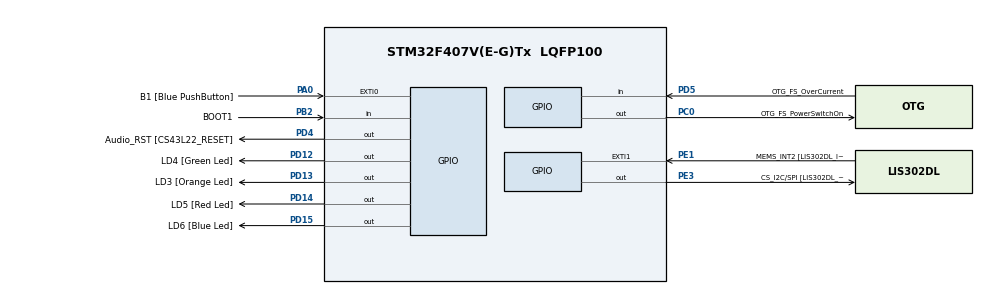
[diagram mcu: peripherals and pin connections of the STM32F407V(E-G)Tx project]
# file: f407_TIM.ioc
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Mcu.Family=STM32F4
Mcu.Name=STM32F407V(E-G)Tx
Mcu.Package=LQFP100
NVIC.PriorityGroup=NVIC_PRIORITYGROUP_0
NVIC.TIM1_UP_TIM10_IRQn=true\:0\:0\:false\:false\:true\:true\:true
PA0-WKUP.GPIO_Label=B1 [Blue PushButton]
PA0-WKUP.Signal=GPXTI0
PA10.GPIO_Label=OTG_FS_ID
PA10.GPIO_Mode=GPIO_MODE_AF_PP
PA10.GPIO_PuPd=GPIO_NOPULL
PA10.GPIO_Speed=GPIO_SPEED_FREQ_LOW
PA10.Signal=USB_OTG_FS_ID
PA11.GPIO_Label=OTG_FS_DM
PA11.GPIO_Mode=GPIO_MODE_AF_PP
PA11.GPIO_PuPd=GPIO_NOPULL
PA11.GPIO_Speed=GPIO_SPEED_FREQ_LOW
PA11.Signal=USB_OTG_FS_DM
PA12.GPIO_Label=OTG_FS_DP
PA12.GPIO_Mode=GPIO_MODE_AF_PP
PA12.GPIO_PuPd=GPIO_NOPULL
PA12.GPIO_Speed=GPIO_SPEED_FREQ_LOW
PA12.Signal=USB_OTG_FS_DP
PA13.GPIO_Label=SWDIO
PA13.Signal=SYS_JTMS-SWDIO
PA14.GPIO_Label=SWCLK
PA14.Signal=SYS_JTCK-SWCLK
PA4.GPIO_Label=I2S3_WS [CS43L22_LRCK]
PA4.GPIO_Mode=GPIO_MODE_AF_PP
PA4.GPIO_PuPd=GPIO_NOPULL
PA4.GPIO_Speed=GPIO_SPEED_FREQ_LOW
PA4.Signal=I2S3_WS
PA5.GPIO_Label=SPI1_SCK [LIS302DL_SCL/SPC]
PA5.GPIO_Mode=GPIO_MODE_AF_PP
PA5.GPIO_PuPd=GPIO_NOPULL
PA5.GPIO_Speed=GPIO_SPEED_FREQ_LOW
PA5.Signal=SPI1_SCK
PA6.GPIO_Label=SPI1_MISO [LIS302DL_SDO]
PA6.GPIO_Mode=GPIO_MODE_AF_PP
PA6.GPIO_PuPd=GPIO_NOPULL
PA6.GPIO_Speed=GPIO_SPEED_FREQ_LOW
PA6.Signal=SPI1_MISO
PA7.GPIO_Label=SPI1_MOSI [LIS302DL_SDA/SDI/SDO]
PA7.GPIO_Mode=GPIO_MODE_AF_PP
PA7.GPIO_PuPd=GPIO_NOPULL
PA7.GPIO_Speed=GPIO_SPEED_FREQ_LOW
PA7.Signal=SPI1_MOSI
PA9.GPIO_Label=VBUS_FS
PA9.GPIO_Mode=GPIO_MODE_INPUT
PA9.GPIO_PuPd=GPIO_NOPULL
PA9.Signal=USB_OTG_FS_VBUS
PB10.GPIO_Label=CLK_IN [MP45DT02_CLK]
PB10.GPIO_Mode=GPIO_MODE_AF_PP
PB10.GPIO_PuPd=GPIO_NOPULL
PB10.GPIO_Speed=GPIO_SPEED_FREQ_LOW
PB10.Signal=I2S2_CK
PB2.GPIO_Label=BOOT1
PB2.GPIO_Mode=GPIO_MODE_INPUT
PB2.GPIO_PuPd=GPIO_NOPULL
PB2.Signal=GPIO_Input
PB3.GPIO_Label=SWO
PB3.Signal=SYS_JTDO-SWO
PB6.GPIO_Label=Audio_SCL [CS43L22_SCL]
PB6.GPIO_Mode=GPIO_MODE_AF_OD
PB6.GPIO_PuPd=GPIO_NOPULL
PB6.GPIO_Speed=GPIO_SPEED_FREQ_LOW
PB6.Signal=I2C1_SCL
PB9.GPIO_Label=Audio_SDA [CS43L22_SDA]
PB9.GPIO_Mode=GPIO_MODE_AF_OD
PB9.GPIO_PuPd=GPIO_NOPULL
PB9.GPIO_Speed=GPIO_SPEED_FREQ_LOW
PB9.Signal=I2C1_SDA
PC0.GPIO_Label=OTG_FS_PowerSwitchOn
PC0.GPIO_PuPd=GPIO_NOPULL
PC0.GPIO_Speed=GPIO_SPEED_FREQ_LOW
PC0.PinState=GPIO_PIN_SET
PC0.Signal=GPIO_Output
PC10.GPIO_Label=I2S3_SCK [CS43L22_SCLK]
PC10.GPIO_Mode=GPIO_MODE_AF_PP
PC10.GPIO_PuPd=GPIO_NOPULL
PC10.GPIO_Speed=GPIO_SPEED_FREQ_LOW
PC10.Signal=I2S3_CK
PC12.GPIO_Label=I2S3_SD [CS43L22_SDIN]
PC12.GPIO_Mode=GPIO_MODE_AF_PP
PC12.GPIO_PuPd=GPIO_NOPULL
PC12.GPIO_Speed=GPIO_SPEED_FREQ_LOW
PC12.Signal=I2S3_SD
PC14-OSC32_IN.GPIO_Label=PC14-OSC32_IN
PC14-OSC32_IN.Signal=RCC_OSC32_IN
PC15-OSC32_OUT.GPIO_Label=PC15-OSC32_OUT
PC15-OSC32_OUT.Signal=RCC_OSC32_OUT
PC3.GPIO_Label=PDM_OUT [MP45DT02_DOUT]
PC3.GPIO_Mode=GPIO_MODE_AF_PP
PC3.GPIO_PuPd=GPIO_NOPULL
PC3.GPIO_Speed=GPIO_SPEED_FREQ_LOW
PC3.Signal=I2S2_SD
PC7.GPIO_Label=I2S3_MCK [CS43L22_MCLK]
PC7.GPIO_Mode=GPIO_MODE_AF_PP
PC7.GPIO_PuPd=GPIO_NOPULL
PC7.GPIO_Speed=GPIO_SPEED_FREQ_LOW
PC7.Signal=I2S3_MCK
PD12.GPIO_Label=LD4 [Green Led]
PD12.GPIO_PuPd=GPIO_NOPULL
PD12.GPIO_Speed=GPIO_SPEED_FREQ_LOW
PD12.Signal=GPIO_Output
PD13.GPIO_Label=LD3 [Orange Led]
PD13.GPIO_PuPd=GPIO_NOPULL
PD13.GPIO_Speed=GPIO_SPEED_FREQ_LOW
PD13.Signal=GPIO_Output
PD14.GPIO_Label=LD5 [Red Led]
PD14.GPIO_PuPd=GPIO_NOPULL
PD14.GPIO_Speed=GPIO_SPEED_FREQ_LOW
PD14.Signal=GPIO_Output
PD15.GPIO_Label=LD6 [Blue Led]
PD15.GPIO_PuPd=GPIO_NOPULL
PD15.GPIO_Speed=GPIO_SPEED_FREQ_LOW
PD15.Signal=GPIO_Output
PD4.GPIO_Label=Audio_RST [CS43L22_RESET]
PD4.GPIO_PuPd=GPIO_NOPULL
PD4.GPIO_Speed=GPIO_SPEED_FREQ_LOW
PD4.Signal=GPIO_Output
PD5.GPIO_Label=OTG_FS_OverCurrent
PD5.GPIO_Mode=GPIO_MODE_INPUT
PD5.GPIO_PuPd=GPIO_NOPULL
PD5.Signal=GPIO_Input
PE1.GPIO_Label=MEMS_INT2 [LIS302DL_INT2]
PE1.GPIO_ModeDefaultEXTI=GPIO_MODE_EVT_RISING
PE1.GPIO_PuPd=GPIO_NOPULL
PE1.Signal=GPXTI1
PE3.GPIO_Label=CS_I2C/SPI [LIS302DL_CS_I2C/SPI]
PE3.GPIO_PuPd=GPIO_NOPULL
PE3.GPIO_Speed=GPIO_SPEED_FREQ_LOW
PE3.Signal=GPIO_Output
PH0-OSC_IN.GPIO_Label=PH0-OSC_IN
PH0-OSC_IN.Mode=HSE-External-Oscillator
PH0-OSC_IN.Signal=RCC_OSC_IN
PH1-OSC_OUT.GPIO_Label=PH1-OSC_OUT
PH1-OSC_OUT.Mode=HSE-External-Oscillator
PH1-OSC_OUT.Signal=RCC_OSC_OUT
ProjectManager.HeapSize=0x200
ProjectManager.StackSize=0x400
ProjectManager.TargetToolchain=STM32CubeIDE
RCC.48MHZClocksFreq_Value=48000000
RCC.AHBFreq_Value=168000000
RCC.APB1CLKDivider=RCC_HCLK_DIV4
RCC.APB1Freq_Value=42000000
RCC.APB1TimFreq_Value=84000000
RCC.APB2CLKDivider=RCC_HCLK_DIV2
RCC.APB2Freq_Value=84000000
RCC.APB2TimFreq_Value=168000000
RCC.CortexFreq_Value=168000000
RCC.HCLKFreq_Value=168000000
RCC.HSE_VALUE=8000000
RCC.HSI_VALUE=16000000
RCC.LSE_VALUE=32768
RCC.PLLM=4
RCC.PLLN=168
RCC.PLLQ=7
RCC.PLLSourceVirtual=RCC_PLLSOURCE_HSE
RCC.SYSCLKFreq_VALUE=168000000
RCC.SYSCLKSource=RCC_SYSCLKSOURCE_PLLCLK
RCC.VCOOutputFreq_Value=336000000
TIM1.ClockDivision=TIM_CLOCKDIVISION_DIV1
TIM1.Period=9999
TIM1.Prescaler=8399
VP_TIM1_VS_ClockSourceINT.Mode=Internal
board=STM32F407G-DISC1

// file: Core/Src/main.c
/* USER CODE BEGIN Header */
/**
  ******************************************************************************
  * @file           : main.c
  * @brief          : Main program body
  ******************************************************************************
  * @attention
  *
  * <h2><center>&copy; Copyright (c) 2020 STMicroelectronics.
  * All rights reserved.</center></h2>
  *
  * This software component is licensed by ST under BSD 3-Clause license,
  * the "License"; You may not use this file except in compliance with the
  * License. You may obtain a copy of the License at:
  *                        opensource.org/licenses/BSD-3-Clause
  *
  ******************************************************************************
  */
/* USER CODE END Header */
#include "main.h"

void SystemClock_Config(void);
static void MX_GPIO_Init(void);
static void MX_TIM1_Init(void);

int main(void)
{

  /* MCU Configuration--------------------------------------------------------*/

  /* Reset of all peripherals, Initializes the Flash interface and the Systick. */

  LL_APB2_GRP1_EnableClock(LL_APB2_GRP1_PERIPH_SYSCFG);
  LL_APB1_GRP1_EnableClock(LL_APB1_GRP1_PERIPH_PWR);

  NVIC_SetPriorityGrouping(NVIC_PRIORITYGROUP_0);

  /* System interrupt init*/

  /* Configure the system clock */
  SystemClock_Config();

  /* Initialize all configured peripherals */
  MX_GPIO_Init();
  MX_TIM1_Init();

  /* Infinite loop */
  while (1)
  {

  }
}

void SystemClock_Config(void)
{
  LL_FLASH_SetLatency(LL_FLASH_LATENCY_5);
  while(LL_FLASH_GetLatency()!= LL_FLASH_LATENCY_5)
  {
  }
  LL_PWR_SetRegulVoltageScaling(LL_PWR_REGU_VOLTAGE_SCALE1);
  LL_RCC_HSE_Enable();

   /* Wait till HSE is ready */
  while(LL_RCC_HSE_IsReady() != 1)
  {

  }
  LL_RCC_PLL_ConfigDomain_SYS(LL_RCC_PLLSOURCE_HSE, LL_RCC_PLLM_DIV_4, 168, LL_RCC_PLLP_DIV_2);
  LL_RCC_PLL_Enable();

   /* Wait till PLL is ready */
  while(LL_RCC_PLL_IsReady() != 1)
  {

  }
  LL_RCC_SetAHBPrescaler(LL_RCC_SYSCLK_DIV_1);
  LL_RCC_SetAPB1Prescaler(LL_RCC_APB1_DIV_4);
  LL_RCC_SetAPB2Prescaler(LL_RCC_APB2_DIV_2);
  LL_RCC_SetSysClkSource(LL_RCC_SYS_CLKSOURCE_PLL);

   /* Wait till System clock is ready */
  while(LL_RCC_GetSysClkSource() != LL_RCC_SYS_CLKSOURCE_STATUS_PLL)
  {

  }
  LL_Init1msTick(168000000);
  LL_SetSystemCoreClock(168000000);
}

static void MX_TIM1_Init(void)
{

  LL_TIM_InitTypeDef TIM_InitStruct = {0};

  /* Peripheral clock enable */
  LL_APB2_GRP1_EnableClock(LL_APB2_GRP1_PERIPH_TIM1);

  /* TIM1 interrupt Init */
  NVIC_SetPriority(TIM1_UP_TIM10_IRQn, NVIC_EncodePriority(NVIC_GetPriorityGrouping(),0, 0));
  NVIC_EnableIRQ(TIM1_UP_TIM10_IRQn);

  TIM_InitStruct.Prescaler = 8399;
  TIM_InitStruct.CounterMode = LL_TIM_COUNTERMODE_UP;
  TIM_InitStruct.Autoreload = 9999;
  TIM_InitStruct.ClockDivision = LL_TIM_CLOCKDIVISION_DIV1;
  TIM_InitStruct.RepetitionCounter = 0;
  LL_TIM_Init(TIM1, &TIM_InitStruct);
  LL_TIM_DisableARRPreload(TIM1);
  LL_TIM_SetClockSource(TIM1, LL_TIM_CLOCKSOURCE_INTERNAL);
  LL_TIM_SetTriggerOutput(TIM1, LL_TIM_TRGO_RESET);
  LL_TIM_DisableMasterSlaveMode(TIM1);
  /* USER CODE BEGIN TIM1_Init 2 */
  LL_TIM_EnableCounter(TIM1);
  LL_TIM_EnableIT_UPDATE(TIM1);
  /* USER CODE END TIM1_Init 2 */

}

static void MX_GPIO_Init(void)
{
  LL_EXTI_InitTypeDef EXTI_InitStruct = {0};
  LL_GPIO_InitTypeDef GPIO_InitStruct = {0};

  /* GPIO Ports Clock Enable */
  LL_AHB1_GRP1_EnableClock(LL_AHB1_GRP1_PERIPH_GPIOE);
  LL_AHB1_GRP1_EnableClock(LL_AHB1_GRP1_PERIPH_GPIOC);
  LL_AHB1_GRP1_EnableClock(LL_AHB1_GRP1_PERIPH_GPIOH);
  LL_AHB1_GRP1_EnableClock(LL_AHB1_GRP1_PERIPH_GPIOA);
  LL_AHB1_GRP1_EnableClock(LL_AHB1_GRP1_PERIPH_GPIOB);
  LL_AHB1_GRP1_EnableClock(LL_AHB1_GRP1_PERIPH_GPIOD);

  /**/
  LL_GPIO_ResetOutputPin(CS_I2C_SPI_GPIO_Port, CS_I2C_SPI_Pin);

  /**/
  LL_GPIO_ResetOutputPin(GPIOD, LD4_Pin|LD3_Pin|LD5_Pin|LD6_Pin
                          |Audio_RST_Pin);

  /**/
  LL_GPIO_SetOutputPin(OTG_FS_PowerSwitchOn_GPIO_Port, OTG_FS_PowerSwitchOn_Pin);

  /**/
  GPIO_InitStruct.Pin = CS_I2C_SPI_Pin;
  GPIO_InitStruct.Mode = LL_GPIO_MODE_OUTPUT;
  GPIO_InitStruct.Speed = LL_GPIO_SPEED_FREQ_LOW;
  GPIO_InitStruct.OutputType = LL_GPIO_OUTPUT_PUSHPULL;
  GPIO_InitStruct.Pull = LL_GPIO_PULL_NO;
  LL_GPIO_Init(CS_I2C_SPI_GPIO_Port, &GPIO_InitStruct);

  /**/
  GPIO_InitStruct.Pin = OTG_FS_PowerSwitchOn_Pin;
  GPIO_InitStruct.Mode = LL_GPIO_MODE_OUTPUT;
  GPIO_InitStruct.Speed = LL_GPIO_SPEED_FREQ_LOW;
  GPIO_InitStruct.OutputType = LL_GPIO_OUTPUT_PUSHPULL;
  GPIO_InitStruct.Pull = LL_GPIO_PULL_NO;
  LL_GPIO_Init(OTG_FS_PowerSwitchOn_GPIO_Port, &GPIO_InitStruct);

  /**/
  GPIO_InitStruct.Pin = PDM_OUT_Pin;
  GPIO_InitStruct.Mode = LL_GPIO_MODE_ALTERNATE;
  GPIO_InitStruct.Speed = LL_GPIO_SPEED_FREQ_LOW;
  GPIO_InitStruct.OutputType = LL_GPIO_OUTPUT_PUSHPULL;
  GPIO_InitStruct.Pull = LL_GPIO_PULL_NO;
  GPIO_InitStruct.Alternate = LL_GPIO_AF_5;
  LL_GPIO_Init(PDM_OUT_GPIO_Port, &GPIO_InitStruct);

  /**/
  GPIO_InitStruct.Pin = I2S3_WS_Pin;
  GPIO_InitStruct.Mode = LL_GPIO_MODE_ALTERNATE;
  GPIO_InitStruct.Speed = LL_GPIO_SPEED_FREQ_LOW;
  GPIO_InitStruct.OutputType = LL_GPIO_OUTPUT_PUSHPULL;
  GPIO_InitStruct.Pull = LL_GPIO_PULL_NO;
  GPIO_InitStruct.Alternate = LL_GPIO_AF_6;
  LL_GPIO_Init(I2S3_WS_GPIO_Port, &GPIO_InitStruct);

  /**/
  GPIO_InitStruct.Pin = SPI1_SCK_Pin|SPI1_MISO_Pin|SPI1_MOSI_Pin;
  GPIO_InitStruct.Mode = LL_GPIO_MODE_ALTERNATE;
  GPIO_InitStruct.Speed = LL_GPIO_SPEED_FREQ_LOW;
  GPIO_InitStruct.OutputType = LL_GPIO_OUTPUT_PUSHPULL;
  GPIO_InitStruct.Pull = LL_GPIO_PULL_NO;
  GPIO_InitStruct.Alternate = LL_GPIO_AF_5;
  LL_GPIO_Init(GPIOA, &GPIO_InitStruct);

  /**/
  GPIO_InitStruct.Pin = BOOT1_Pin;
  GPIO_InitStruct.Mode = LL_GPIO_MODE_INPUT;
  GPIO_InitStruct.Pull = LL_GPIO_PULL_NO;
  LL_GPIO_Init(BOOT1_GPIO_Port, &GPIO_InitStruct);

  /**/
  GPIO_InitStruct.Pin = CLK_IN_Pin;
  GPIO_InitStruct.Mode = LL_GPIO_MODE_ALTERNATE;
  GPIO_InitStruct.Speed = LL_GPIO_SPEED_FREQ_LOW;
  GPIO_InitStruct.OutputType = LL_GPIO_OUTPUT_PUSHPULL;
  GPIO_InitStruct.Pull = LL_GPIO_PULL_NO;
  GPIO_InitStruct.Alternate = LL_GPIO_AF_5;
  LL_GPIO_Init(CLK_IN_GPIO_Port, &GPIO_InitStruct);

  /**/
  GPIO_InitStruct.Pin = LD4_Pin|LD3_Pin|LD5_Pin|LD6_Pin
                          |Audio_RST_Pin;
  GPIO_InitStruct.Mode = LL_GPIO_MODE_OUTPUT;
  GPIO_InitStruct.Speed = LL_GPIO_SPEED_FREQ_LOW;
  GPIO_InitStruct.OutputType = LL_GPIO_OUTPUT_PUSHPULL;
  GPIO_InitStruct.Pull = LL_GPIO_PULL_NO;
  LL_GPIO_Init(GPIOD, &GPIO_InitStruct);

  /**/
  GPIO_InitStruct.Pin = I2S3_MCK_Pin|I2S3_SCK_Pin|I2S3_SD_Pin;
  GPIO_InitStruct.Mode = LL_GPIO_MODE_ALTERNATE;
  GPIO_InitStruct.Speed = LL_GPIO_SPEED_FREQ_LOW;
  GPIO_InitStruct.OutputType = LL_GPIO_OUTPUT_PUSHPULL;
  GPIO_InitStruct.Pull = LL_GPIO_PULL_NO;
  GPIO_InitStruct.Alternate = LL_GPIO_AF_6;
  LL_GPIO_Init(GPIOC, &GPIO_InitStruct);

  /**/
  GPIO_InitStruct.Pin = VBUS_FS_Pin;
  GPIO_InitStruct.Mode = LL_GPIO_MODE_INPUT;
  GPIO_InitStruct.Pull = LL_GPIO_PULL_NO;
  LL_GPIO_Init(VBUS_FS_GPIO_Port, &GPIO_InitStruct);

  /**/
  GPIO_InitStruct.Pin = OTG_FS_ID_Pin|OTG_FS_DM_Pin|OTG_FS_DP_Pin;
  GPIO_InitStruct.Mode = LL_GPIO_MODE_ALTERNATE;
  GPIO_InitStruct.Speed = LL_GPIO_SPEED_FREQ_LOW;
  GPIO_InitStruct.OutputType = LL_GPIO_OUTPUT_PUSHPULL;
  GPIO_InitStruct.Pull = LL_GPIO_PULL_NO;
  GPIO_InitStruct.Alternate = LL_GPIO_AF_10;
  LL_GPIO_Init(GPIOA, &GPIO_InitStruct);

  /**/
  GPIO_InitStruct.Pin = OTG_FS_OverCurrent_Pin;
  GPIO_InitStruct.Mode = LL_GPIO_MODE_INPUT;
  GPIO_InitStruct.Pull = LL_GPIO_PULL_NO;
  LL_GPIO_Init(OTG_FS_OverCurrent_GPIO_Port, &GPIO_InitStruct);

  /**/
  GPIO_InitStruct.Pin = Audio_SCL_Pin|Audio_SDA_Pin;
  GPIO_InitStruct.Mode = LL_GPIO_MODE_ALTERNATE;
  GPIO_InitStruct.Speed = LL_GPIO_SPEED_FREQ_LOW;
  GPIO_InitStruct.OutputType = LL_GPIO_OUTPUT_OPENDRAIN;
  GPIO_InitStruct.Pull = LL_GPIO_PULL_UP;
  GPIO_InitStruct.Alternate = LL_GPIO_AF_4;
  LL_GPIO_Init(GPIOB, &GPIO_InitStruct);

  /**/
  LL_SYSCFG_SetEXTISource(LL_SYSCFG_EXTI_PORTA, LL_SYSCFG_EXTI_LINE0);

  /**/
  LL_SYSCFG_SetEXTISource(LL_SYSCFG_EXTI_PORTE, LL_SYSCFG_EXTI_LINE1);

  /**/
  EXTI_InitStruct.Line_0_31 = LL_EXTI_LINE_0;
  EXTI_InitStruct.LineCommand = ENABLE;
  EXTI_InitStruct.Mode = LL_EXTI_MODE_IT;
  EXTI_InitStruct.Trigger = LL_EXTI_TRIGGER_RISING;
  LL_EXTI_Init(&EXTI_InitStruct);

  /**/
  EXTI_InitStruct.Line_0_31 = LL_EXTI_LINE_1;
  EXTI_InitStruct.LineCommand = ENABLE;
  EXTI_InitStruct.Mode = LL_EXTI_MODE_EVENT;
  EXTI_InitStruct.Trigger = LL_EXTI_TRIGGER_RISING;
  LL_EXTI_Init(&EXTI_InitStruct);

  /**/
  LL_GPIO_SetPinPull(B1_GPIO_Port, B1_Pin, LL_GPIO_PULL_NO);

  /**/
  LL_GPIO_SetPinPull(MEMS_INT2_GPIO_Port, MEMS_INT2_Pin, LL_GPIO_PULL_NO);

  /**/
  LL_GPIO_SetPinMode(B1_GPIO_Port, B1_Pin, LL_GPIO_MODE_INPUT);

  /**/
  LL_GPIO_SetPinMode(MEMS_INT2_GPIO_Port, MEMS_INT2_Pin, LL_GPIO_MODE_INPUT);

}

void Error_Handler(void)
{
}

/************************ (C) COPYRIGHT STMicroelectronics *****END OF FILE****/
